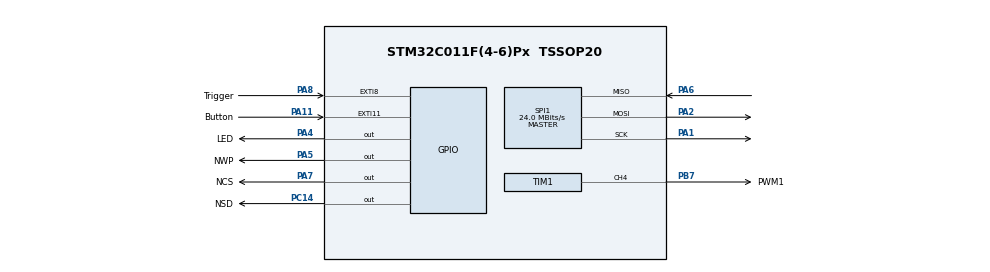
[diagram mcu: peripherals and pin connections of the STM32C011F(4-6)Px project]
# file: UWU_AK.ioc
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Mcu.Family=STM32C0
Mcu.Name=STM32C011F(4-6)Px
Mcu.Package=TSSOP20
NVIC.EXTI4_15_IRQn=true\:0\:0\:false\:false\:true\:true\:true\:true
NVIC.SPI1_IRQn=true\:1\:0\:true\:false\:true\:true\:true\:true
NVIC.TIM1_BRK_UP_TRG_COM_IRQn=true\:3\:0\:true\:false\:true\:true\:true\:true
NVIC.TIM1_CC_IRQn=true\:3\:0\:true\:false\:true\:true\:true\:true
PA1.GPIO_Speed=GPIO_SPEED_FREQ_VERY_HIGH
PA1.Mode=Full_Duplex_Master
PA1.Signal=SPI1_SCK
PA11\ [PA9].GPIO_Label=Button
PA11\ [PA9].GPIO_ModeDefaultEXTI=GPIO_MODE_IT_FALLING
PA11\ [PA9].Signal=GPXTI11
PA13.Mode=Serial_Wire
PA13.Signal=DEBUG_SWDIO
PA14-BOOT0.Mode=Serial_Wire
PA14-BOOT0.Signal=DEBUG_SWCLK
PA2.GPIO_Speed=GPIO_SPEED_FREQ_VERY_HIGH
PA2.Mode=Full_Duplex_Master
PA2.Signal=SPI1_MOSI
PA4.GPIO_Label=LED
PA4.Signal=GPIO_Output
PA5.GPIO_Label=NWP
PA5.Signal=GPIO_Output
PA6.GPIO_Speed=GPIO_SPEED_FREQ_VERY_HIGH
PA6.Mode=Full_Duplex_Master
PA6.Signal=SPI1_MISO
PA7.GPIO_Label=NCS
PA7.Signal=GPIO_Output
PA8.GPIO_Label=Trigger
PA8.GPIO_ModeDefaultEXTI=GPIO_MODE_IT_FALLING
PA8.Signal=GPXTI8
PB7.GPIO_Label=PWM1
PB7.Signal=S_TIM1_CH4
PC14-OSCX_IN\ (PC14).GPIO_Label=NSD
PC14-OSCX_IN\ (PC14).Signal=GPIO_Output
ProjectManager.HeapSize=0x200
ProjectManager.StackSize=0x400
ProjectManager.TargetToolchain=STM32CubeIDE
RCC.ADCFreq_Value=48000000
RCC.AHBFreq_Value=48000000
RCC.CortexFreq_Value=48000000
RCC.EXTERNAL_CLOCK_VALUE=12288000
RCC.HCLKFreq_Value=48000000
RCC.HSE_VALUE=8000000
RCC.HSISYSCLKDivider=RCC_HSI_DIV1
RCC.HSI_VALUE=48000000
RCC.LSE_VALUE=32768
RCC.SYSCLKFreq_VALUE=48000000
SH.S_TIM1_CH4.0=TIM1_CH4,PWM Generation4 CH4
SPI1.CalculateBaudRate=24.0 MBits/s
SPI1.Direction=SPI_DIRECTION_2LINES
SPI1.Mode=SPI_MODE_MASTER
SPI1.NSSPMode=SPI_NSS_PULSE_DISABLE
SPI1.VirtualType=VM_MASTER
TIM1.Channel-PWM\ Generation4\ CH4=TIM_CHANNEL_4
TIM1.OCIdleState_4=TIM_OCIDLESTATE_SET
TIM1.Period=256-1
TIM1.Prescaler=0
VP_TIM1_VS_ClockSourceINT.Mode=Internal
board=custom

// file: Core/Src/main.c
/* USER CODE BEGIN Header */
/**
  ******************************************************************************
  * @file           : main.c
  * @brief          : Main program body
  ******************************************************************************
  * @attention
  *
  * Copyright (c) 2025 STMicroelectronics.
  * All rights reserved.
  *
  * This software is licensed under terms that can be found in the LICENSE file
  * in the root directory of this software component.
  * If no LICENSE file comes with this software, it is provided AS-IS.
  *
  ******************************************************************************
  */
/* USER CODE END Header */
#include "main.h"
#include "spi.h"
#include "tim.h"
#include "gpio.h"

/* USER CODE BEGIN Includes */
#include "system.h"
/* USER CODE END Includes */

/* USER CODE BEGIN PD */
#define DEFAULT_STARTUP_VAL (0x80)
/* USER CODE END PD */

void SystemClock_Config(void);

int main(void)
{

  /* MCU Configuration--------------------------------------------------------*/

  /* Reset of all peripherals, Initializes the Flash interface and the Systick. */
  LL_APB2_GRP1_EnableClock(LL_APB2_GRP1_PERIPH_SYSCFG);
  LL_APB1_GRP1_EnableClock(LL_APB1_GRP1_PERIPH_PWR);

  /* SysTick_IRQn interrupt configuration */
  NVIC_SetPriority(SysTick_IRQn, 3);

  /* Configure the system clock */
  SystemClock_Config();

  /* Initialize all configured peripherals */
  MX_GPIO_Init();
  MX_SPI1_Init();
  MX_TIM1_Init();

  /* Infinite loop */
  /* USER CODE BEGIN WHILE */

  SystemBoot();

  /*---------------LEFT HERE FOR FUTURE ME------------------------
  //LL_TIM_EnableCounter(TIM1);
  //LL_TIM_OC_SetMode(TIM1, LL_TIM_CHANNEL_CH4, LL_TIM_OCMODE_PWM1);
  ----------------------------------------------------------------*/

  while (1)
  {
	NewMain();

    /* USER CODE END WHILE */

  }
}

void SystemClock_Config(void)
{

  LL_FLASH_SetLatency(LL_FLASH_LATENCY_1);

  /* HSI configuration and activation */
  LL_RCC_HSI_Enable();
  while(LL_RCC_HSI_IsReady() != 1)
  {
  }

  LL_RCC_HSI_SetCalibTrimming(64);
  LL_RCC_SetHSIDiv(LL_RCC_HSI_DIV_1);
  /* Set AHB prescaler*/
  LL_RCC_SetAHBPrescaler(LL_RCC_HCLK_DIV_1);

  /* Sysclk activation on the HSI */
  LL_RCC_SetSysClkSource(LL_RCC_SYS_CLKSOURCE_HSI);
  while(LL_RCC_GetSysClkSource() != LL_RCC_SYS_CLKSOURCE_STATUS_HSI)
  {
  }

  /* Set APB1 prescaler*/
  LL_RCC_SetAPB1Prescaler(LL_RCC_APB1_DIV_1);
  LL_Init1msTick(48000000);
  /* Update CMSIS variable (which can be updated also through SystemCoreClockUpdate function) */
  LL_SetSystemCoreClock(48000000);
}

void Error_Handler(void)
{
  __disable_irq();
  while (1)
  {
  }
}
